# LCD_1.0 register map
Vendor: Texas Instruments
Peripheral module from a debugger description file (folder mspm0l122x_l222x).
Registers are 32-bit, read-write, no defined reset value unless marked. A register's access mark holds for its fields unless they carry their own. Offsets are as the file gives them; lines under a group give offsets from that group; [hi:lo] are bit positions; {n}, {i} and the like mark numbered series; 'fields as' and 'values as' point back to an identical list; <NAME> marks a mode.

## LCD
0x800 LCD_PWREN — Power enable
  [0] ENABLE — Enable the power
    0=DISABLE (Disable Power); 1=ENABLE (Enable Power)
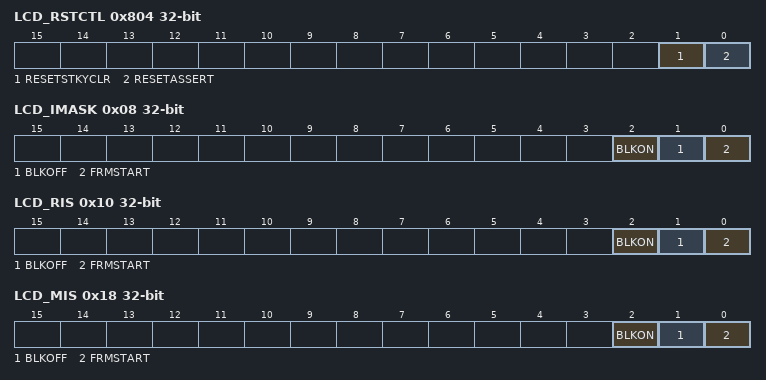
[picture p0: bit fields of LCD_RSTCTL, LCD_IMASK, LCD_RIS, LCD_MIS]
0x804 LCD_RSTCTL — Reset Control
  [1] RESETSTKYCLR — Clear the RESETSTKY bit in the STAT register
    0=NOP (Writing 0 has no effect); 1=CLR (Clear reset sticky bit)
  [0] RESETASSERT — Assert reset to the peripheral
    0=NOP (Writing 0 has no effect); 1=ASSERT (Assert reset)
0x814 LCD_STAT ro — Status Register
  [16] RESETSTKY — This bit indicates, if the peripheral was reset, since this bit was cleared by RESETSTKYCLR in the RSTCTL register
    0=NORES (The peripheral has not been reset since this bit was last cleared by RESETSTKYCLR in the RSTCTL register); 1=RESET (The peripheral was reset since the last bit clear)
0x1020 LCD_INT_EVENT0 group
  0x00 LCD_IIDX ro — Interrupt index
    [7:0] STAT — LCD Module Interrupt Vector Value. This register provides the highes priority interrupt index. A read clears the corresponding interrupt flag in RIS and MISC. 15h-1Fh = Reserved
      0=NO_INTR (No interrupt pending); 1=FRAME_START (Start of new frame interrupt); 2=BLK_OFF (Blinking segments off interrupt); 3=BLK_ON (Blinking segments on interrupt)
  0x08 LCD_IMASK — Interrupt mask
    [all] fields
      0=CLR (Clear Interrupt Mask); 1=SET (Set Interrrupt Mask)
    [2] BLKON — Blinkking segments on.
    [1] BLKOFF — Blinking segments off.
    [0] FRMSTART — Start of new LCD frame.
  0x10 LCD_RIS — Raw interrupt status
    [all] fields
      0=CLR (Interrupt flag cleared); 1=SET (Interrupt flag set)
    [2] BLKON — Blinking segments turned on.
    [1] BLKOFF — Blinking segments turned off interrupt flag.
    [0] FRMSTART — Set in start of a new frame.
  0x18 LCD_MIS — Masked interrupt status
    [2] BLKON — Masked BLKON interrupt flag
      0=CLR (Masked interrupt flag cleared); 1=SET (Masked interrupt flag set)
    [1] BLKOFF — Masked BLKOFF interrupt flag
      values as BLKON
    [0] FRMSTART — Master FRMSTART interrupt flag
      0=CLR (Interrupt flag cleared); 1=SET (Interrupt flag set)
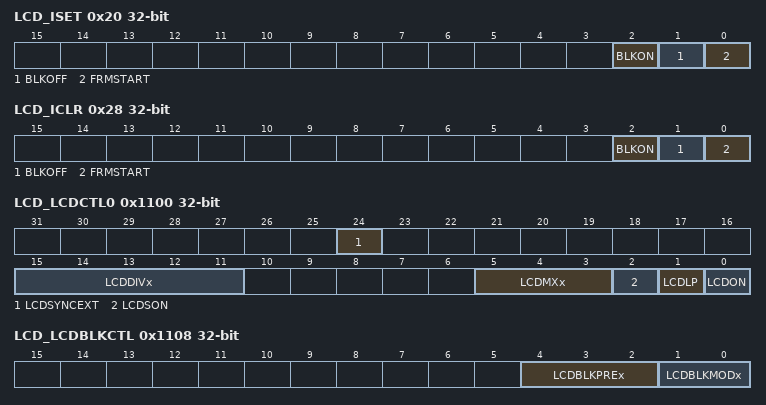
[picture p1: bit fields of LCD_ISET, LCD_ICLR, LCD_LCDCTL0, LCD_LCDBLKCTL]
  0x20 LCD_ISET — Interrupt set
    [all] fields
      0=NO_EFFECT (Writing 0 has no effect); 1=SET (Set corresponding RIS flag)
    [2] BLKON — Set BLKON RIS flag
    [1] BLKOFF — Set BLKOFF RIS flag
    [0] FRMSTART — Set FRMSTART RIS flag.
  0x28 LCD_ICLR — Interrupt clear
    [all] fields
      0=NO_EFFECT (Writing 0 has no effect); 1=CLR (Clear corresponding RIS flag)
    [2] BLKON — Clear BLKON RIS flag
    [1] BLKOFF — Clear BLKOFF RIS flag
    [0] FRMSTART — Clear FRMSTART RIS flag
0x10E0 LCD_EVT_MODE ro — Event Mode
  [1:0] INT0_CFG — Event line mode select for event corresponding to [IPSTANDARD.INT_EVENT0]
    0=DISABLE (The interrupt or event line is disabled.); 1=SOFTWARE (The interrupt or event line is in software mode. Software must clear the RIS.); 2=HARDWARE (The interrupt or event line is in hardware mode. The hardware (another module) clears automatically the associated RIS flag.)
0x1100 LCD_LCDCTL0 — LCD control register 0
  [24] LCDSYNCEXT
    0=LCD_EXT_SYNC_OFF (External eynchronization off.); 1=LCD_EXT_SYNC_ON (External synchronization on.)
  [15:11] LCDDIVx — LCD frequency divider. Together with LCDMXx, the LCD frequency fLCD is calculated as fLCD = fSOURCE / ((LCDDIVx + 1) * Value[LCDMXx]). Change only while LCDON = 0. 00000b = Divide by 1 00001b = Divide by 2 . 11110b = Divide by 31 11111b = Divide by 32
    {v}=DIV_BY_{v+1} (Divide by {v+1}) (v=0..31)
  [5:3] LCDMXx — LCD mux rate. These bits select the LCD mode. Change only while LCDON = 0. 000b = Static 001b = 2-mux 010b = 3-mux 011b = 4-mux 100b = 5-mux 101b = 6-mux 110b = 7-mux 111b = 8-mux
    0=Mx_STATIC (Static); {v}=MX_{v+1} ({v+1}-mux) (v=1..7)
  [2] LCDSON — LCD segments on. This bit supports flashing LCD applications by turning off all segment lines, while leaving the LCD timing generator and R33 enabled. 0b = All LCD segments are off. 1b = All LCD segments are enabled and on or off according to their corresponding memory location.
    0=LCD_SEG_OFF (All LCD segments are off.); 1=LCD_SEG_ON (All LCD segments are enabled and on or off according to their corresponding memory location.)
  [1] LCDLP — LCD low-power waveform. This bit is only applicable for 1/3 bias mode, that is, for LCDBIASSEL = 0. 0b = Standard LCD waveforms on segment and common lines selected. 1b = Low-power LCD waveforms on segment and common lines selected.
    0=STD_LCD (Standard LCD waveforms); 1=LP_LCD (Low power LCD waveforms)
  [0] LCDON — LCD on. This bit turns the LCD module on or off. 0b = LCD module off 1b = LCD module on
    0=LCD_MOD_DISABLE (LCD module off); 1=LCD_MOD_ENABLE (LCD module on)
0x1108 LCD_LCDBLKCTL — LCD blicking control register
  [4:2] LCDBLKPREx — Clock prescaler for blinking frequency.
    0=DIV_BY_2 (Divide by 2); 1=DIV_BY_4 (Divide by 4); 2=DIV_BY_8 (Divide by 8); 3=DIV_BY_16 (Divide by 16); 4=DIV_BY_32 (Divide by 32); 5=DIV_BY_64 (Divide by 64); 6=DIV_BY_128 (Divide by 128); 7=DIV_BY_256 (Divide by 256)
  [1:0] LCDBLKMODx — Blinking mode 00b = Blinking disabled. 01b = Blinking of individual segments as enabled in blinking memory register LCDBMx. In mux mode >5 blinking is disabled. 10b = Blinking of all segments 11b = Switching between display contents as stored in LCDMx and LCDBMx memory registers. In mux mode >5 blinking is disabled.
    0=BLINK_DISABLE (Blinking disabled.); 1=BLINK_SELECED (Blinking of individual segments as enabled in blinking memory register LCDBMx. In mux mode >5 blinking is disabled.); 2=BLINK_ALL (Blinking of all segments); 3=BKINK_TOGGLE (Switching between display contents as stored in LCDMx and LCDBMx memory registers. In mux mode >5 blinking is disabled.)
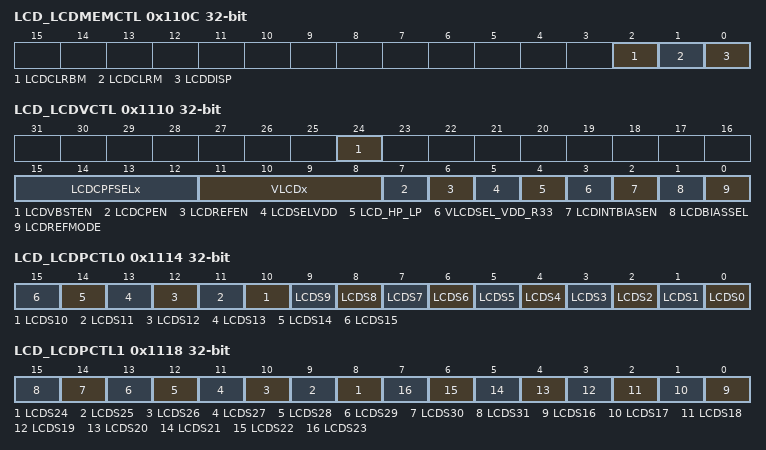
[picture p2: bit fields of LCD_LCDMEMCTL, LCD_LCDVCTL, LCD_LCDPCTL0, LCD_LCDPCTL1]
0x110C LCD_LCDMEMCTL — LCD memory control LCD memory control register
  [2] LCDCLRBM — Clear LCD blinking memory Clears all blinking memory registers LCDBMx. The bit is automatically reset when the blinking memory is cleared. Setting this bit in 5-mux mode and above has no effect. It is immediately reset again. 0b = Contents of blinking memory registers LCDBMx remain unchanged 1b = Clear content of all blinking memory registers LCDBMx
    0=NO_CLR_BLNK_MEM_REGS (Contents of blinking memory registers LCDBMx remain unchanged); 1=CLR_BLNK_MEM_REGS (Clear content of all blinking memory registers LCDBMx)
  [1] LCDCLRM — Clear LCD memory Clears all LCD memory registers LCDMx. The bit is automatically reset when the LCD memory is cleared. 0b = Contents of LCD memory registers LCDMx remain unchanged 1b = Clear content of all LCD memory registers LCDMx
    0=NO_CLR_LCD_MEM_REGS (Contents of LCD memory registers LCDMx remain unchanged); 1=CLR_LCD_MEM_REGS (Clear content of all LCD memory registers LCDMx)
  [0] LCDDISP — Select LCD memory registers for display When LCDBLKMODx = 00, LCDDISP can be set by software. The bit is cleared in LCDBLKMODx = 01 and LCDBLKMODx = 10 or if a mux mode =5 is selected and cannot be changed by software. When LCDBLKMODx = 11, this bit reflects the currently displayed memory but cannot be changed by software. When returning to LCDBLKMODx = 00 the bit is cleared. 0b = Display content of LCD memory registers LCDMx 1b = Display content of LCD blinking memory registers LCDBMx
    0=SEL_LCD_MEM_REGS (Display content of LCD memory registers LCDMx); 1=SEL_BLNK_MEM_REGS (Display content of LCD blinking memory registers LCDBMx)
0x1110 LCD_LCDVCTL — LCD voltage control register
  [24] LCDVBSTEN — Enables the voltage boost circuitry which provides a boosted VDDA voltage. This boosted voltage is to be used in the switch controls, when the VDDA supply is less than 1.6V.
    0=Disable; 1=ENABLE
  [15:12] LCDCPFSELx — Charge pump frequency selection. 0000b = 32.768 kHz / 1 / 8 = 4.096 kHz 0001b = 32.768 kHz / 2 / 8 = 2.048 kHz 0010b = 32.768 kHz / 3 / 8 = 1.365 kHz 0011b = 32.768 kHz / 4 / 8 = 1.024 kHz 0100b = 32.768 kHz / 5 / 8 = 819 Hz 0101b = 32.768 kHz / 6 / 8 = 682 Hz 0110b = 32.768 kHz / 7 / 8 = 585 Hz 0111b = 32.768 kHz / 8 / 8 = 512 Hz 1000b = 32.768 kHz / 9 / 8 = 455 Hz 1001b = 32.768 kHz / 10 / 8 = 409 Hz 1010b = 32.768 kHz / 11 / 8 = 372 Hz 1011b = 32.768 kHz / 12 / 8 = 341 Hz 1100b = 32.768 kHz / 13 / 8 = 315 Hz 1101b = 32.768 kHz / 14 / 8 = 292 Hz 1110b = 32.768 kHz / 15 / 8 = 273 Hz 1111b = 32.768 kHz / 16 / 8 = 256 Hz
    0=DIV_BY_1_BY_8 (32.768 kHz / 1 / 8 = 4.096 kHz); 1=DIV_BY_2_BY_8 (32.768 kHz / 2 / 8 = 2.048 kHz); 2=DIV_BY_3_BY_8 (32.768 kHz / 3 / 8 = 1.365 kHz); 3=DIV_BY_4_BY_8 (32.768 kHz / 4 / 8 = 1.024 kHz); 4=DIV_BY_5_BY_8 (32.768 kHz / 5 / 8 = 819 Hz); 5=DIV_BY_6_BY_8 (32.768 kHz / 6 / 8 = 682 Hz); 6=DIV_BY_7_BY_8 (32.768 kHz / 7 / 8 = 585 Hz); 7=DIV_BY_8_BY_8 (32.768 kHz / 8 / 8 = 512 Hz); 8=DIV_BY_9_BY_8 (32.768 kHz / 9 / 8 = 455 Hz); 9=DIV_BY_10_BY_8 (32.768 kHz / 10 / 8 = 409 Hz); 10=DIV_BY_11_BY_8 (32.768 kHz / 11 / 8 = 372 Hz); 11=DIV_BY_12_BY_8 (32.768 kHz / 12 / 8 = 341 Hz); 12=DIV_BY_13_BY_8 (32.768 kHz / 13 / 8 = 315 Hz); 13=DIV_BY_14_BY_8 (32.768 kHz / 14 / 8 = 292 Hz); 14=DIV_BY_15_BY_8 (32.768 kHz / 15 / 8 = 273 Hz); 15=DIV_BY_16_BY_8 (32.768 kHz / 16 / 8 = 256 Hz)
  [11:8] VLCDx — Internal reference voltage select on R13.
    0=SEL_2P60V (2.60 V); 1=SEL_2P66V (2.66 V); 2=SEL_2P72V (2.72 V); 3=SEL_2P78V (2.78 V); 4=SEL_2P84V (2.84 V); 5=SEL_2P90V (2.90 V); 6=SEL_2P96V (2.96 V); 7=SEL_3P02V (3.02 V); 8=SEL_3P08V (3.08 V); 9=SEL_3P14V (3.14 V); 10=SEL_3P20V (3.20 V); 11=SEL_3P26V (3.26 V); 12=SEL_3P32V (3.32 V); 13=SEL_3P38V (3.38 V); 14=SEL_3P44V (3.44 V); 15=SEL_3P50V (3.50 V)
  [7] LCDCPEN — Charge pump enable 0b = Charge pump disabled(1) 1b = Charge pump enabled when VLCD is generated internally (VLCDEXT = 0) and VLCDx > 0 or VLCDREFx > 0.
    0=CP_DISABLE (Charge pump disabled(1)); 1=CP_ENABLE (Charge pump enabled when VLCD is generated internally (VLCDEXT = 0) and VLCDx > 0 or VLCDREFx > 0.)
  [6] LCDREFEN — Internal reference voltage enable on R13 0b = Internal reference voltage disabled 1b = Internal reference voltage enabled
    0=INT_REF_DISABLE (Internal reference voltage disabled); 1=INT_REF_ENABLE (Internal reference voltage enabled)
  [5] LCDSELVDD — Selects if R33 is supplied either from AVDD internally or from charge pump 0b = R33 connected to external supply 1b = R33 internally connected to AVDD
    0=SEL_EXT_SUPPLY (R33 connected to external supply); 1=SEL_AVDD (R33 internally connected to AVDD)
  [4] LCD_HP_LP — High-power or Low-power LCD. This bit is only effective when the internal bias voltage resistor divider is used, that is, when LCDINTBIASEN = 1. It selects the resistor ladder that is used to generate the bias voltages for the LCD. 0b = Low-power LCD is used 1b = Higher-power LCD is used
    0=LP_MODE (Low-power LCD is used); 1=HP_MODE (Higher-power LCD is used)
  [3] VLCDSEL_VDD_R33 — Selects if the LCD bias voltage V1 is sourced from the R33 pin or from the internal supply voltage AVDD This bit is only effective when the internal bias voltage resistor divider is used, that is, when LCDINTBIASEN = 1 0b = V1 is sourced from R33 1b = V1 is sourced internally from AVDD
    0=SEL_R33 (V1 is sourced from R33); 1=SEL_AVDD (V1 is sourced internally from AVDD)
  [2] LCDINTBIASEN — Enables the internal bias voltage resistor divider. The actual voltage source used for the resistor divider is selected by the VLCDSEL_VDD_R33 bit configuration. 0b = Internal bias voltage resistor divider is disabled 1b = Internal bias voltage resistor divider is enabledDD
    0=INT_BIAS_DISABLE (Internal bias voltage resistor divider is disabled); 1=INT_BIAS_ENABLE (Internal bias voltage resistor divider is enabled)
  [1] LCDBIASSEL — Bias select. LCDBIASSEL is ignored in static mode as well as for 2-mux, 3-mux and 4-mux LCD modes. For 5-mux to 8-mux modes: 0b = 1/3 bias 1b = 1/4 bias
    0=ONE_BY_3_BIAS (1/3 bias); 1=ONE_BY_4_BIAS (1/4 bias)
  [0] LCDREFMODE — Selects whether R13 voltage is switched or in static mode 0b = Static mode 1b = Switched mode
    0=STATIC_MODE; 1=SWITCHED_MODE
0x1114 LCD_LCDPCTL0 — LCD port control register 0
  [all] fields
    0=SEL_PORT (Multiplexed pins are port functions.); 1=SEL_LCD (Pins are LCD functions.)
  [n] LCDS{n} (n=0..15) — LCD pin {n} enable. This bit affects only pins with multiplexed functions. Dedicated LCD pins are always LCD function. 0b = Multiplexed pins are port functions. 1b = Pins are LCD functions.
0x1118 LCD_LCDPCTL1 — LCD port control register 1
  [all] fields
    values as the fields of LCD_LCDPCTL0
  [n-16] LCDS{n} (n=24..31) — LCD pin {n} enable. This bit affects only pins with multiplexed functions. Dedicated LCD pins are always LCD function. 0b = Multiplexed pins are port functions. 1b = Pins are LCD functions.
  [n-16] LCDS{n} (n=16..23) — LCD segment line {n} enable. This bit affects only pins with multiplexed functions. Dedicated LCD pins are always LCD function. 0b = Multiplexed pins are port functions. 1b = Pins are LCD functions.
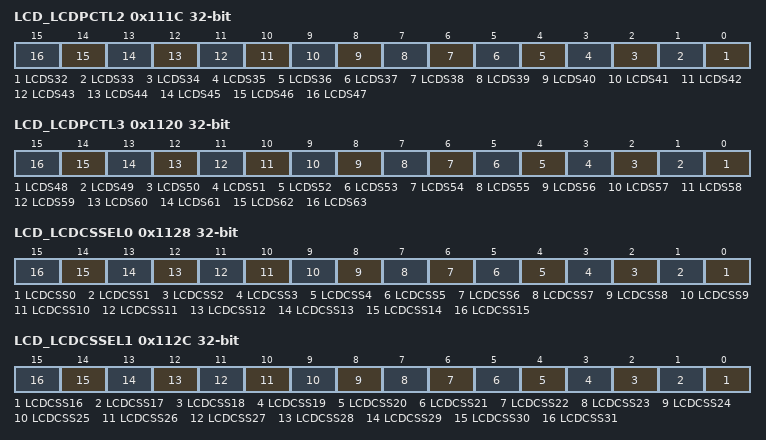
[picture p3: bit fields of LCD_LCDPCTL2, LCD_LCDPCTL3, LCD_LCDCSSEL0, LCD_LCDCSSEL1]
0x111C LCD_LCDPCTL2 — LCD port control register 2
  [all] fields
    values as the fields of LCD_LCDPCTL0
  [n-32] LCDS{n} (n=32..47) — LCD pin {n} enable. This bit affects only pins with multiplexed functions. Dedicated LCD pins are always LCD function. 0b = Multiplexed pins are port functions. 1b = Pins are LCD functions.
0x1120 LCD_LCDPCTL3 — LCD port control register 3
  [all] fields
    values as the fields of LCD_LCDPCTL0
  [n-48] LCDS{n} (n=48..63) — LCD pin {n} enable. This bit affects only pins with multiplexed functions. Dedicated LCD pins are always LCD function. 0b = Multiplexed pins are port functions. 1b = Pins are LCD functions.
0x1128 LCD_LCDCSSEL0 — LCD common segment select register 0
  [all] fields
    0=SEL_SEG (Segment line); 1=SEL_COM (Common line)
  [n] LCDCSS{n} (n=0..15) — Selects pin L{n} as either common or segment line. 0b = Segment line 1b = Common line
0x112C LCD_LCDCSSEL1 — LCD common segment select register 1
  [all] fields
    0=SEL_SEG (Segment line); 1=SEL_COM (Common line)
  [n-16] LCDCSS{n} (n=16..31) — Selects pin L{n} as either common or segment line. 0b = Segment line 1b = Common line
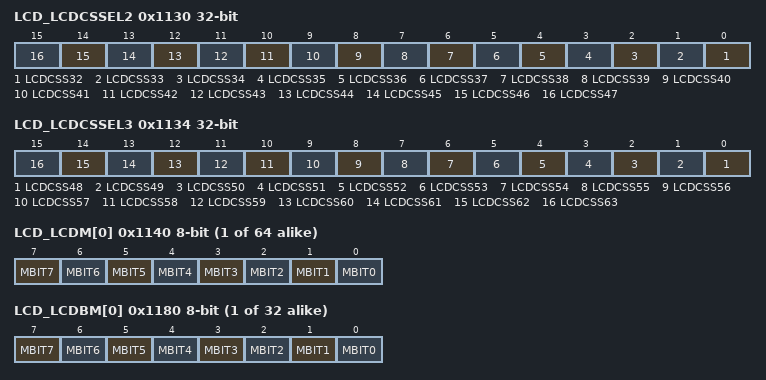
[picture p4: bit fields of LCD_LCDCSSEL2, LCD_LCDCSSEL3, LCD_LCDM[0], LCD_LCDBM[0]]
0x1130 LCD_LCDCSSEL2 — LCD common segment select register 2
  [all] fields
    0=SEL_SEG (Segment line); 1=SEL_COM (Common line)
  [n-32] LCDCSS{n} (n=32..47) — Selects pin L{n} as either common or segment line. 0b = Segment line 1b = Common line
0x1134 LCD_LCDCSSEL3 — LCD common segment select register 3
  [all] fields
    0=SEL_SEG (Segment line); 1=SEL_COM (Common line)
  [n-48] LCDCSS{n} (n=48..63) — Selects pin L{n} as either common or segment line. 0b = Segment line 1b = Common line
{0x1140+i} LCD_LCDM[{i}] (i=0..63) 8-bit — LCD memory index register
  [7] MBIT7 — If LCD pin L[2*index+1] is selected as segment line (LCDCSS[2*index+1] = 0b) and LCD mux rate is 4-mux (LCDMXx=011b): 0b = LCD segment off 1b = LCD segment on If LCD pin L[2*index+1] is selected as common line (LCDCSS[2*index+1] = 1b): 0b = Pin L[2*index+1] not used as COM3 1b = Pin L[2*index+1] is used as COM3 If LCD pin L(index) is selected as segment line (LCDCSS(index) = 0b) and LCD mux rate is 8-mux (LCDMXx = 111b): 0b = LCD segment off 1b = LCD segment on If LCD pin L(index) is selected as common line (LCDCSS(index) = 1b): 0b = Pin L(index) not used as COM7 1b = Pin L(index) is used as COM7
    0=OFF (LCD segment/common off); 1=ON (LCD segment/common on)
  [6] MBIT6 — If LCD pin L[2*index+1] is selected as segment line (LCDCSS[2*index+1] = 0b) and LCD mux rate is 3- or 4-mux (010b <= LCDMXx <= 011b): 0b = LCD segment off 1b = LCD segment on If LCD pin L[2*index+1] is selected as common line (LCDCSS[2*index+1] = 1b): 0b = Pin L[2*index+1] not used as COM2 1b = Pin L[2*index+1] is used as COM2 If LCD pin L(index) is selected as segment line (LCDCSS(index) = 0b) and LCD mux rate is 7- or 8-mux (LCDMXx >= 110b): 0b = LCD segment off 1b = LCD segment on If LCD pin L(index) is selected as common line (LCDCSS(index) = 1b): 0b = Pin L(index) not used as COM6 1b = Pin L(index) is used as COM6
  [5] MBIT5 — If LCD pin L[2*index+1] is selected as segment line (LCDCSS[2*index+1] = 0b) and LCD mux rate is 2-, 3- or 4-mux (001b <= LCDMXx <= 011b): 0b = LCD segment off 1b = LCD segment on If LCD pin L[2*index+1] is selected as common line (LCDCSS[2*index+1] = 1b): 0b = Pin L[2*index+1] not used as COM1 1b = Pin L[2*index+1] is used as COM1 If LCD pin L(index) is selected as segment line (LCDCSS(index) = 0b) and LCD mux rate is 6-, 7- or 8-mux (LCDMXx >= 101b): 0b = LCD segment off 1b = LCD segment on If LCD pin L(index) is selected as common line (LCDCSS(index) = 1b): 0b = Pin L(index) not used as COM5 1b = Pin L(index) is used as COM5
    0=OFF (LCD segment/common off); 1=ON (LCD segment/common on)
  [4] MBIT4 — If LCD pin L[2*index+1] is selected as segment line (LCDCSS[2*index+1] = 0b) and LCD mux rate is static, 2-, 3- or 4-mux (000 <= LCDMXx <= 011b) 0b = LCD segment off 1b = LCD segment on If LCD pin L[2*index+1] is selected as common line (LCDCSS[2*index+1] = 1b): 0b = Pin L[2*ndex+1] not used as COM0 1b = Pin L[2*ndex+1] is used as COM0
    0=OFF (LCD segment/common off); 1=ON (LCD segment/common on)
  [3] MBIT3 — If LCD pin L(index) is selected as segment line (LCDCSS(index) = 0b) and LCD mux rate is 4-mux (LCDMXx=011b): 0b = LCD segment off 1b = LCD segment on If LCD pin L[2*index] is selected as common line (LCDCSS[2*index] = 1b): 0b = Pin L[2*index] not used as COM3 1b = Pin L[2*index] is used as COM3 If LCD pin L(index) is selected as segment line (LCDCSS(index) = 0b) and LCD mux rate is 5-, 6-, 7- or 8-mux (LCDMXx >= 100b): 0b = LCD segment off 1b = LCD segment on If LCD pin L(index) is selected as common line (LCDCSS(index) = 1b): 0b = Pin L(index) not used as COM3 1b = Pin L(index) is used as COM3
    0=OFF (LCD segment/common off); 1=ON (LCD segment/common on)
  [2] MBIT2 — If LCD pin L[2*index] is selected as segment line (LCDCSS[2*index] = 0b) and LCD mux rate is 3- or 4-mux (010b <= LCDMXx <= 011b): 0b = LCD segment off 1b = LCD segment on If LCD pin L[2*index] is selected as common line (LCDCSS[2*index] = 1b): 0b = Pin L[2*index] not used as COM2 1b = Pin L[2*index] is used as COM2 If LCD pin L(index) is selected as segment line (LCDCSS(index) = 0b) and LCD mux rate is 5-, 6-, 7- or 8-mux (LCDMXx >= 100b): 0b = LCD segment off 1b = LCD segment on If LCD pin L(index) is selected as common line (LCDCSS(index) = 1b): 0b = Pin L[index-1] not used as COM2 1b = Pin L[index-1] is used as COM2
    0=OFF (LCD segment/common off); 1=ON (LCD segment/common on)
  [1] MBIT1 — If LCD pin L[2*index] is selected as segment line (LCDCSS[2*index] = 0b) and LCD mux rate is 2-, 3- or 4-mux (001b <= LCDMXx <= 011b): 0b = LCD segment off 1b = LCD segment on If LCD pin L[2*index] is selected as common line (LCDCSS[2*index] = 1b): 0b = Pin L[2*index] not used as COM1 1b = Pin L[2*index] is used as COM1 If LCD pin L(index) is selected as segment line (LCDCSS(index) = 0b) and LCD mux rate is 5-, 6-, 7- or 8-mux (LCDMXx >= 100b): 0b = LCD segment off 1b = LCD segment on If LCD pin L(index) is selected as common line (LCDCSS(index) = 1b): 0b = Pin L(index) not used as COM1 1b = Pin L(index) is used as COM1
    0=OFF (LCD segment/common off); 1=ON (LCD segment/common on)
  [0] MBIT0 — If LCD L[2*index] is selected as segment line (LCDCSS[2*index] = 0b) and LCD mux rate is static, 2-, 3- or 4-mux (000b <= LCDMXx <= 011b) 0b = LCD segment off 1b = LCD segment on If LCD pin L[2*index] is selected as common line (LCDCSS[2*index] = 1b): 0b = Pin L[2*index] not used as COM0 1b = Pin L[2*index] is used as COM0 If LCD pin L(index) is selected as segment line (LCDCSS(index) = 0b) and LCD mux rate is 5-, 6-, 7- or 8-mux (LCDMXx >= 100b): 0b = LCD segment off 1b = LCD segment on If LCD pin L(index) is selected as common line (LCDCSS(index) = 1b): 0b = Pin L(index) not used as COM0 1b = Pin L(index) is used as COM0
    0=OFF (LCD segment/common off); 1=ON (LCD segment/common on)
{0x1180+i} LCD_LCDBM[{i}] (i=0..31) 8-bit — LCD blinking memory index register
  [all] fields
    0=OFF (LCD segment/common off); 1=ON (LCD segment/common on)
  [7] MBIT7 — If LCD pin L[2*index+1] is selected as segment line (LCDCSS[2*index+1] = 0b) and LCD mux rate is 4-mux (LCDMXx=011b): 0b = LCD segment off 1b = LCD segment on If LCD pin L[2*index+1] is selected as common line (LCDCSS[2*index+1] = 1b): 0b = Pin L[2*index+1] not used as COM3 1b = Pin L[2*index+1] is used as COM3 If LCD pin L(index) is selected as segment line (LCDCSS(index) = 0b) and LCD mux rate is 8-mux (LCDMXx = 111b): 0b = LCD segment off 1b = LCD segment on If LCD pin L(index) is selected as common line (LCDCSS(index) = 1b): 0b = Pin L(index) not used as COM7 1b = Pin L(index) is used as COM7
  [6] MBIT6 — If LCD pin L[2*index+1] is selected as segment line (LCDCSS[2*index+1] = 0b) and LCD mux rate is 3- or 4-mux (010b <= LCDMXx <= 011b): 0b = LCD segment off 1b = LCD segment on If LCD pin L[2*index+1] is selected as common line (LCDCSS[2*index+1] = 1b): 0b = Pin L[2*index+1] not used as COM2 1b = Pin L[2*index+1] is used as COM2 If LCD pin L(index) is selected as segment line (LCDCSS(index) = 0b) and LCD mux rate is 7- or 8-mux (LCDMXx >= 110b): 0b = LCD segment off 1b = LCD segment on If LCD pin L(index) is selected as common line (LCDCSS(index) = 1b): 0b = Pin L(index) not used as COM6 1b = Pin L(index) is used as COM6
  [5] MBIT5 — If LCD pin L[2*index+1] is selected as segment line (LCDCSS[2*index+1] = 0b) and LCD mux rate is 2-, 3- or 4-mux (001b <= LCDMXx <= 011b): 0b = LCD segment off 1b = LCD segment on If LCD pin L[2*index+1] is selected as common line (LCDCSS[2*index+1] = 1b): 0b = Pin L[2*index+1] not used as COM1 1b = Pin L[2*index+1] is used as COM1 If LCD pin L(index) is selected as segment line (LCDCSS(index) = 0b) and LCD mux rate is 6-, 7- or 8-mux (LCDMXx >= 101b): 0b = LCD segment off 1b = LCD segment on If LCD pin L(index) is selected as common line (LCDCSS(index) = 1b): 0b = Pin L(index) not used as COM5 1b = Pin L(index) is used as COM5
  [4] MBIT4 — If LCD pin L[2*index+1] is selected as segment line (LCDCSS[2*index+1] = 0b) and LCD mux rate is static, 2-, 3- or 4-mux (000b <= LCDMXx <= 011b) 0b = LCD segment off 1b = LCD segment on If LCD pin L[2*index+1] is selected as common line (LCDCSS[2*index+1] = 1b): 0b = Pin L[2*ndex+1] not used as COM0 1b = Pin L[2*ndex+1] is used as COM0
  [3] MBIT3 — If LCD pin L(index) is selected as segment line (LCDCSS(index) = 0b) and LCD mux rate is 4-mux (LCDMXx=011b): 0b = LCD segment off 1b = LCD segment on If LCD pin L[2*index] is selected as common line (LCDCSS[2*index] = 1b): 0b = Pin L[2*index] not used as COM3 1b = Pin L[2*index] is used as COM3 If LCD pin L(index) is selected as segment line (LCDCSS(index) = 0b) and LCD mux rate is 5-, 6-, 7- or 8-mux (LCDMXx >= 100b): 0b = LCD segment off 1b = LCD segment on If LCD pin L(index) is selected as common line (LCDCSS(index) = 1b): 0b = Pin L(index) not used as COM3 1b = Pin L(index) is used as COM3
  [2] MBIT2 — If LCD pin L[2*index] is selected as segment line (LCDCSS[2*index] = 0b) and LCD mux rate is 3- or 4-mux (010b <= LCDMXx <= 011b): 0b = LCD segment off 1b = LCD segment on If LCD pin L[2*index] is selected as common line (LCDCSS[2*index] = 1b): 0b = Pin L[2*index] not used as COM2 1b = Pin L[2*index] is used as COM2 If LCD pin L(index) is selected as segment line (LCDCSS(index) = 0b) and LCD mux rate is 5-, 6-, 7- or 8-mux (LCDMXx >= 100b): 0b = LCD segment off 1b = LCD segment on If LCD pin L(index) is selected as common line (LCDCSS(index) = 1b): 0b = Pin L[index-1] not used as COM2 1b = Pin L[index-1] is used as COM2
  [1] MBIT1 — If LCD pin L[2*index] is selected as segment line (LCDCSS[2*index] = 0b) and LCD mux rate is 2-, 3- or 4-mux (001b <= LCDMXx <= 011b): 0b = LCD segment off 1b = LCD segment on If LCD pin L[2*index] is selected as common line (LCDCSS[2*index] = 1b): 0b = Pin L[2*index] not used as COM1 1b = Pin L[2*index] is used as COM1 If LCD pin L(index) is selected as segment line (LCDCSS(index) = 0b) and LCD mux rate is 5-, 6-, 7- or 8-mux (LCDMXx >= 100b): 0b = LCD segment off 1b = LCD segment on If LCD pin L(index) is selected as common line (LCDCSS(index) = 1b): 0b = Pin L(index) not used as COM1 1b = Pin L(index) is used as COM1
  [0] MBIT0 — If LCD L[2*index] is selected as segment line (LCDCSS[2*index] = 0b) and LCD mux rate is static, 2-, 3- or 4-mux (000b <= LCDMXx <= 011b) 0b = LCD segment off 1b = LCD segment on If LCD pin L[2*index] is selected as common line (LCDCSS[2*index] = 1b): 0b = Pin L[2*index] not used as COM0 1b = Pin L[2*index] is used as COM0 If LCD pin L(index) is selected as segment line (LCDCSS(index) = 0b) and LCD mux rate is 5-, 6-, 7- or 8-mux (LCDMXx >= 100b): 0b = LCD segment off 1b = LCD segment on If LCD pin L(index) is selected as common line (LCDCSS(index) = 1b): 0b = Pin L(index) not used as COM0 1b = Pin L(index) is used as COM0
